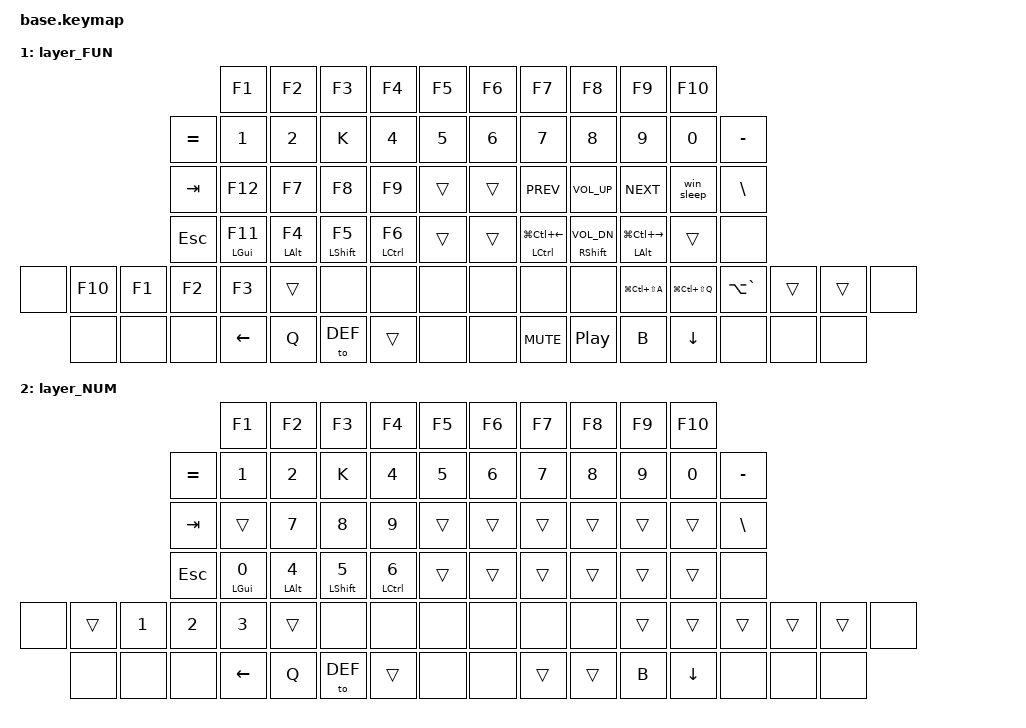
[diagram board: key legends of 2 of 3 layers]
#include <behaviors.dtsi>
#include <dt-bindings/zmk/keys.h>
#include "zmk-helpers/key-labels/glove80.h"

#include <dt-bindings/zmk/bt.h>

#include "zmk-helpers/helper.h"
#include "zmk-helpers/unicode-chars/ainain

setting code-chars/german.dtsi"

#define Layer_DEF 0
#define Layer_NAV 1
#define Layer_FN 2
#define Layer_SYS 4

#include "combos.dtsi"  // requires layer aliases
#include "mouse.dtsi"
#include "extra_keys.h"

/* Global settings */

#define QUICK_TAP_MS 175


/* Homerow modsrrrrrrrtttttttttmmmmmmmmmmm|IIIrI */

#define KEYS_L LT0 LT1 LT2 LT3 LT4 LM0 LM1 LM2 LM3 LM4 LB0 LB1 LB2 LB3 LB4 LF1 LF2 LF3 LF4 LF5 LN0 LN1 LN2 LN3 LN4 LN5 // left hand
#define KEYS_R RT0 RT1 RT2 RT3 RT4 RM0 RM1 RM2 RM3 RM4 RB0 RB1 RB2 RB3 RB4 RF1 RF2 RF3 RF4 RF5 // right hand
#define THUMBS LH2 LH1 LH0 RH0 RH1 RH2                                      // thumbs

#define MAKE_HRM(NAME, HOLD, TAP, TRIGGER_POS) \
    ZMK_HOLD_TAP(NAME, \
        flavor = "balanced"; \
        tapping-term-ms = <280>; \
        quick-tap-ms = <QUICK_TAP_MS>; \
        require-prior-idle-ms = <350>; \
        bindings = <HOLD>, <TAP>; \
        hold-trigger-key-positions = <TRIGGER_POS>; \ 
        hold-trigger-on-release; \
    )
MAKE_HRM(hml, &kp, &kp, KEYS_R THUMBS)  // left-hand HRMs
MAKE_HRM(hmr, &kp, &kp, KEYS_L THUMBS)  // right-hand HRMs

MAKE_HRM(hml_repeat, &kp, &key_repeat, KEYS_R THUMBS)  // used for HRM-combo
MAKE_HRM(hmr_lpar_lt, &kp, &lpar_lt, KEYS_L THUMBS)    // "    "   "   "
MAKE_HRM(hmr_rpar_gt, &kp, &rpar_gt, KEYS_L THUMBS)    // "    "   "   "

/* Nav cluster */

// long-tap action on hold, short-tap action on all interrupts
#define MT_CORE \
    flavor = "tap-preferred"; \
    tapping-term-ms = <220>; \
    quick-tap-ms = <220>; \
    hold-trigger-key-positions = <0>;

&mt { MT_CORE };
ZMK_HOLD_TAP(mt_home, bindings = <&masked_home>, <&kp>; MT_CORE)
ZMK_HOLD_TAP(mt_end, bindings = <&masked_end>, <&kp>; MT_CORE)

#define NAV_LEFT  &mt_home 0   LEFT    // tap: left  | long-tap: beginning of line
#define NAV_RIGHT &mt_end 0    RIGHT   // tap: right | long-tap: end       of line
#define NAV_UP    &mt LC(HOME) UP      // tap: up    | long-tap: beginning of document
#define NAV_DOWN  &mt LC(END)  DOWN    // tap: down  | long-tap: end       of document
#define NAV_BSPC  &mt LC(BSPC) BSPC    // tap: bspc  | long-tap: delete word backward
#define NAV_DEL   &mt LC(DEL)  DEL     // tap: del   | long-tap: delete word forward

// mask CTRL when holding left/right to avoid accidental jumps to beginning/end of document
#define MASK_MODS(NAME, MODS, BINDING) \
    ZMK_MOD_MORPH(NAME, \
        bindings = <BINDING>, <BINDING>; \
        mods = <MODS>; \
    )
MASK_MODS(masked_home, (MOD_LCTL), &kp HOME)
MASK_MODS(masked_end,  (MOD_LCTL), &kp END)

/* Caps-word, num-word and smart-mouse */

// tap: sticky-shift | shift + tap/ double-tap: caps-word | hold: shift
ZMK_MOD_MORPH(smart_shft,
    bindings = <&sk LSHFT>, <&caps_word>;
    mods = <(MOD_LSFT)>;
)
&caps_word {  // mods deactivate caps-word, requires PR #1451
    /delete-property/ ignore-modifiers;
};

// tap: num-word | double-tap: sticky num-layer | hold: num-layer
#define SMART_NUM &smart_num NUM 0
ZMK_HOLD_TAP(smart_num,
    flavor = "balanced";
    tapping-term-ms = <200>;
    quick-tap-ms = <QUICK_TAP_MS>;
    bindings = <&mo>, <&num_dance>;
)
ZMK_TAP_DANCE(num_dance,
    tapping-term-ms = <200>;
    bindings = <&num_word>, <&sl NUM>;  // reverse this for sticky-num on single tap
)
&num_word {  // num-word, requires PR #1451
    layers = <NUM>;
    continue-list = <BSPC DEL DOT COMMA PLUS MINUS STAR FSLH EQUAL>;
};

// smart-mouse, requires PR #1366
ZMK_TRI_STATE(smart_mouse,
    bindings = <&tog MOUSE>, <&none>, <&tog MOUSE>;
    ignored-key-positions = <LT1 LT3 RT0 RT1 RT2 RT3 RT4 RM1 RM2 RM3 RB1 RB2 RB3 RH0 RH1>;
    ignored-layers = <MOUSE>;
)

/* Custom behaviors */

// Alt+Tab swapper, requires PR #1366
ZMK_TRI_STATE(swapper,
    bindings = <&kt LALT>, <&kp TAB>, <&kt LALT>;
    ignored-key-positions = <LT2>;
)

// Sticky layer + sticky shift (workaround for issue #1421)
ZMK_STICKY_KEY(sls,
    release-after-ms = <1000>;
    bindings = <&uc_shift>;
    ignore-modifiers;
)
ZMK_MACRO(uc_shift,
    wait-ms = <0>;
    tap-ms = <1>;
    bindings = <&macro_press &mo UC &kp LSHFT>
             , <&macro_pause_for_release>
             , <&macro_release &mo UC &kp LSHFT>;
)

// reuse basic mod-morph scheme
#define SIMPLE_MORPH(NAME, MOD, BINDING1, BINDING2) \
    ZMK_MOD_MORPH(NAME, \
        mods = <(MOD_L ## MOD|MOD_R ## MOD)>; \
        bindings = <BINDING1>, <BINDING2>; \
    )

// tap: comma | shift + tap: semicolon | ctrl + shift + tap: <
SIMPLE_MORPH(comma_morph, SFT, &kp COMMA, &comma_inner_morph)
SIMPLE_MORPH(comma_inner_morph, CTL, &kp SEMICOLON, &kp LESS_THAN)

// tap: dot | shift + tap: colon | ctrl + shift + tap: >
SIMPLE_MORPH(dot_morph, SFT, &kp DOT, &dot_inner_morph)
SIMPLE_MORPH(dot_inner_morph, CTL, &kp COLON, &kp GREATER_THAN)

// tap: qmark | shift + tap: excl
SIMPLE_MORPH(qexcl, SFT, &kp QMARK, &kp EXCL)
SIMPLE_MORPH(quote, SFT, &kp LS(SINGLE_QUOTE), &kp SINGLE_QUOTE)

// tap: left/right parenthesis | shft + tap: less-than/greater-than
SIMPLE_MORPH(lpar_lt, SFT, &kp LPAR, &kp LT)
SIMPLE_MORPH(rpar_gt, SFT, &kp RPAR, &kp GT)

// tap: space | shift + tap: dot -> space -> sticky shift | hold: activate layer
ZMK_HOLD_TAP(lt_spc,
    flavor = "balanced";
    tapping-term-ms = <200>;
    quick-tap-ms = <QUICK_TAP_MS>;
    bindings = <&mo>, <&spc_morph>;
)
SIMPLE_MORPH(spc_morph, SFT, &kp SPACE, &dot_spc)
ZMK_MACRO(dot_spc,
    wait-ms = <0>;
    tap-ms = <5>;
    bindings = <&kp DOT &kp SPACE &sk LSHFT>;
)

// tap: backspace | lshft + tap: delete | rshft + tap: shift-delete
ZMK_MOD_MORPH(bs_del,
    bindings = <&kp BSPC>, <&kp DEL>;
    mods = <(MOD_LSFT|MOD_RSFT)>;
    keep-mods = <MOD_RSFT>;
)

// tap: copy | double-tap: cut
ZMK_TAP_DANCE(copy_cut,
    tapping-term-ms = <200>;
    bindings = <&kp LC(INS)>, <&kp LC(X)>;
)

// Windows sleep key
ZMK_MACRO(win_sleep,
    wait-ms = <500>;
    tap-ms = <50>;
    bindings = <&kp LG(X) &kp U &kp S>;
)

// misc aliases
#define CANCEL      &kp K_CANCEL             // cancel caps-word, num-word and smart-mouse
#define DSK_PREV    &hmr LCTRL LG(LC(LEFT))   // previous desktop
#define DSK_NEXT    &hmr LALT LG(LC(RIGHT)) // next     desktop
#define PIN_WIN     &kp LG(LC(LS(Q)))        // pin window across desktops
#define PIN_APP     &kp LG(LC(LS(A)))        // pin application across desktops
#define DSK_MGR     &kp LA(GRAVE)            // desktop manager
#define VOL_DOWN    &hmr RSHFT C_VOL_DN


/* Keymap */                             

/ {
    keymap {
        compatible = "zmk,keymap";
                layer_DEF {
            bindings = <
//╭─────────────┬─────────────┬─────────────┬─────────────┬─────────────╮                                                                                                            ╭─────────────┬─────────────┬─────────────┬──────────────┬─────────────╮
     &kp F1         &kp F2        &kp F3       &kp F4        &kp F5                                                                                                                    &kp F6        &kp F7        &kp F8        &kp F9        &kp F10 
//├─────────────┼─────────────┼─────────────┼─────────────┼─────────────┼───────────╮                                                                                 ╭──────────────┼─────────────┼─────────────┼─────────────┼──────────────┼─────────────┤
     &kp EQUAL      &kp N1        &kp N2       &kp K         &kp N4        &kp N5                                                                                       &kp N6         &kp N7        &kp N8        &kp N9        &kp N0        &kp MINUS                
//╰─────────────┴─────────────┴─────────────┴─────────────┴─────────────┴───────────╯                                                                                 ╰──────────────┴─────────────┴─────────────┴─────────────┴──────────────┴─────────────╯
         
//╭─────────────┬──────────────┬─────────────┬─────────────┬─────────────┬────────────╮                                                                               ╭─────────────┬─────────────┬─────────────┬─────────────┬──────────────┬──────────────╮
    &none         &kp ESC        &kp G         &kp H         &kp C          &kp Z                                                                                          &trans       &kp V         &kp L         &kp B         &kp SQT       &none  
//├─────────────┤──────────────┼─────────────┼─────────────┼─────────────┼────────────┤                                                                               ├─────────────┼─────────────┼─────────────┼─────────────┼──────────────┼──────────────┤
    &none         &hml LGUI O    &hml LALT A   &hml LSHFT I  &hml LCTRL N   &qexcl                                                                                         &trans       &hmr LCTRL T  &hmr RSHFT R  &hmr LALT E   &hmr LGUI S   &none  
//├─────────────┤──────────────┼─────────────┼─────────────┼─────────────┼────────────┤ ╭──────────────┬─────────────┬───────╮╭────────┬──────────────┬─────────────╮ ├─────────────┼─────────────┼─────────────┼─────────────┼──────────────┼──────────────┤
    &kp LSHFT     &kp J          &kp F         &kp U         &kp P          &trans         &mo NAV       &lt FN RET    &none    &none     &mo SYS       &mo NUM           &trans        &kp M         &kp D         &kp Y         &kp X         &kp RSHFT  
//├─────────────┼──────────────┤─────────────┼─────────────┤─────────────┼────────────╯ ├──────────────┼─────────────┼───────┤├────────┼──────────────┼─────────────┤ ╰─────────────┼─────────────┼─────────────┤─────────────┼──────────────┤──────────────┤
    &bootloader   &none         &comma_morph   &quote        &kp Q                         &kp SPACE     &kp BACKSPACE &none    &none     &none         &kp TAB                         &kp W         &kp RET      &dot_morph     &none         &bootloader
//╰─────────────┴──────────────┴─────────────┴─────────────┴─────────────╯              ╰──────────────┴─────────────┴───────╯╰────────┴──────────────┴─────────────╯               ╰─────────────┴─────────────┴─────────────┴──────────────┴──────────────╯                                           
            >;
        };
    };
};
    
/ {
    keymap {
        compatible = "zmk,keymap";
                layer_NAV {      
                    bindings = <             
//╭──────╮ ╭─────────────┬─────────────┬─────────────┬─────────────┬─────────────╮ ╭──────╮ ╭─────────────┬─────────────┬─────────────┬─────────────┬─────────────╮ ╭──────╮
    \
                &kp F1    &kp F2 &kp F3 &kp F4 &kp F5                 &kp F6 &kp F7 &kp F8 &kp F9 &kp F10 \
                &kp EQUAL &kp N1 &kp N2 &kp K &kp N4 &kp N5   &kp N6 &kp N7 &kp N8 &kp N9 &kp N0 &kp MINUS \
                &kp TAB     &trans           &trans           &kp LS(TAB)   &swapper      &trans             X_MT     &kp PG_UP     NAV_BSPC      NAV_UP        NAV_DEL       &trans             &kp BACKSLASH
//├──────┤ ├─────────────┼─────────────┼─────────────┼─────────────┼─────────────┤ ├──────┤ ├─────────────┼─────────────┼─────────────┼─────────────┼─────────────┤ ├──────┤
    &kp ESC     &sk LGUI      &sk LALT      &sk LSHFT     &sk LCTRL     &trans             X_MM     &kp PG_DN     NAV_LEFT      NAV_DOWN      NAV_RIGHT     &kp RET         &none
//├──────┤ ├─────────────┼─────────────┼─────────────┼─────────────┼─────────────┤ ├──────┤ ├─────────────┼─────────────┼─────────────┼─────────────┼─────────────┤ ├──────┤
    &none     &trans           &trans           &trans           &trans           &trans             &none &none &none       &none &none &none     &kp INS       &kp TAB       &kp LT        &kp GT        &trans             &none
//├──────┤ ╰─────────────┼─────────────┴─────────────┼─────────────┼─────────────┤ ├──────┤ ├─────────────┼─────────────┼─────────────┴───────────────────────────╯ ├──────┤
    &none &none &none &kp LEFT &kp Q                                               &to DEF           &trans              &none &none     &trans           CANCEL                                                    &kp B &kp DOWN &none &none &none
//╰──────╯                                           ╰─────────────┴─────────────╯ ╰──────╯ ╰─────────────┴─────────────╯                                           ╰──────╯
>;
        };
    };
};

/ {
    keymap {
        compatible = "zmk,keymap";
                layer_FUN {   
                    bindings = <
//╭──────╮ ╭─────────────┬─────────────┬─────────────┬─────────────┬─────────────╮ ╭──────╮ ╭─────────────┬─────────────┬─────────────┬─────────────┬─────────────╮ ╭──────╮
    \
                &kp F1    &kp F2 &kp F3 &kp F4 &kp F5                 &kp F6 &kp F7 &kp F8 &kp F9 &kp F10 \
                &kp EQUAL &kp N1 &kp N2 &kp K &kp N4 &kp N5   &kp N6 &kp N7 &kp N8 &kp N9 &kp N0 &kp MINUS \
                &kp TAB     &kp F12       &kp F7        &kp F8        &kp F9        &trans                  &trans           &kp C_PREV    &kp C_VOL_UP  &kp C_NEXT    &win_sleep      &kp BACKSLASH
//├──────┤ ├─────────────┼─────────────┼─────────────┼─────────────┼─────────────┤ ├──────┤ ├─────────────┼─────────────┼─────────────┼─────────────┼─────────────┤ ├──────┤
    &kp ESC     &hml LGUI F11 &hml LALT F4  &hml LSHFT F5 &hml LCTRL F6 &trans                  &trans           DSK_PREV      VOL_DOWN      DSK_NEXT      &trans             &none
//├──────┤ ├─────────────┼─────────────┼─────────────┼─────────────┼─────────────┤ ├──────┤ ├─────────────┼─────────────┼─────────────┼─────────────┼─────────────┤ ├──────┤
    &none     &kp F10       &kp F1        &kp F2        &kp F3        &trans             &none &none &none       &none &none &none     PIN_APP       PIN_WIN       DSK_MGR       &trans           &trans             &none
//├──────┤ ╰─────────────┼─────────────┴─────────────┼─────────────┼─────────────┤ ├──────┤ ├─────────────┼─────────────┼─────────────┴───────────────────────────╯ ├──────┤
    &none &none &none &kp LEFT &kp Q                                               &to DEF           &trans              &none &none     &kp C_MUTE    &kp C_PP                                                  &kp B &kp DOWN &none &none &none
//╰──────╯                                           ╰─────────────┴─────────────╯ ╰──────╯ ╰─────────────┴─────────────╯                                           ╰──────╯
>;
        };
    };
};

/ {
    keymap {
        compatible = "zmk,keymap";
                layer_NUM {  
                    bindings = <
//╭──────╮ ╭─────────────┬─────────────┬─────────────┬─────────────┬─────────────╮ ╭──────╮ ╭─────────────┬─────────────┬─────────────┬─────────────┬─────────────╮ ╭──────╮
    \
                &kp F1    &kp F2 &kp F3 &kp F4 &kp F5                 &kp F6 &kp F7 &kp F8 &kp F9 &kp F10 \
                &kp EQUAL &kp N1 &kp N2 &kp K &kp N4 &kp N5   &kp N6 &kp N7 &kp N8 &kp N9 &kp N0 &kp MINUS \
                &kp TAB     &trans           &kp N7        &kp N8        &kp N9        &trans                  &trans           &trans           &trans           &trans           &trans             &kp BACKSLASH
//├──────┤ ├─────────────┼─────────────┼─────────────┼─────────────┼─────────────┤ ├──────┤ ├─────────────┼─────────────┼─────────────┼─────────────┼─────────────┤ ├──────┤
    &kp ESC     &hml LGUI N0  &hml LALT N4  &hml LSHFT N5 &hml LCTRL N6 &trans                  &trans           &trans           &trans           &trans           &trans             &none
//├──────┤ ├─────────────┼─────────────┼─────────────┼─────────────┼─────────────┤ ├──────┤ ├─────────────┼─────────────┼─────────────┼─────────────┼─────────────┤ ├──────┤
    &none     &trans           &kp N1        &kp N2        &kp N3        &trans             &none &none &none       &none &none &none     &trans           &trans           &trans           &trans           &trans             &none
//├──────┤ ╰─────────────┼─────────────┴─────────────┼─────────────┼─────────────┤ ├──────┤ ├─────────────┼─────────────┼─────────────┴───────────────────────────╯ ├──────┤
    &none &none &none &kp LEFT &kp Q                                               &to DEF           &trans              &none &none     &trans           &trans                                                       &kp B &kp DOWN &none &none &none
//╰──────╯                                           ╰─────────────┴─────────────╯ ╰──────╯ ╰─────────────┴─────────────╯                                           ╰──────╯
>;
        };
    };
};

// / {
//     keymap {
//         compatible = "zmk,keymap";
//                 layer_SYS {  
//                     bindings = <
// //╭──────╮ ╭─────────────┬─────────────┬─────────────┬─────────────┬─────────────╮ ╭──────╮ ╭─────────────┬─────────────┬─────────────┬─────────────┬─────────────╮ ╭──────╮
//     \
//                 &kp F1    &kp F2 &kp F3 &kp F4 &kp F5                 &kp F6 &kp F7 &kp F8 &kp F9 &kp F10 \
//                 &kp EQUAL &kp N1 &kp N2 &kp K &kp N4 &kp N5   &kp N6 &kp N7 &kp N8 &kp N9 &kp N0 &kp MINUS \
//                 &kp TAB                                &bt BT_SEL 0 &bt BT_SEL 1 &bt BT_SEL 2 &bt BT_SEL 3 &bt BT_CLR                                X_MT     &trans           &trans           &trans           &trans           &trans             &kp BACKSLASH
// //├──────┤ ├─────────────┼─────────────┼─────────────┼─────────────┼─────────────┤ ├──────┤ ├─────────────┼─────────────┼─────────────┼─────────────┼─────────────┤ ├──────┤
//     &kp ESC     &trans           &trans           &trans           &trans           &bootloader     X_MM     &bootloader   &trans           &trans           &trans           &trans             &none
// //├──────┤ ├─────────────┼─────────────┼─────────────┼─────────────┼─────────────┤ ├──────┤ ├─────────────┼─────────────┼─────────────┼─────────────┼─────────────┤ ├──────┤
//     &none     &trans           &trans           &trans           &trans           &sys_reset      &none &none &none       &none &none &none     &sys_reset    &trans           &trans           &trans           &trans             &none
// //├──────┤ ╰─────────────┼─────────────┴─────────────┼─────────────┼─────────────┤ ├──────┤ ├─────────────┼─────────────┼─────────────┴───────────────────────────╯ ├──────┤
//     &none &none &none &kp LEFT &kp Q                                               &to DEF           &trans              &none &none     &trans           &trans                                                       &kp B &kp DOWN &none &none &none
// //╰──────╯                                           ╰─────────────┴─────────────╯ ╰──────╯ ╰─────────────┴─────────────╯                                           ╰──────╯
// >;
//         };
//     };
// };


// ZMK_LAYER(mouse,
// //╭──────╮ ╭─────────────┬─────────────┬─────────────┬─────────────┬─────────────╮ ╭──────╮ ╭─────────────┬─────────────┬─────────────┬─────────────┬─────────────╮ ╭──────╮
//     \
                // &kp F1    &kp F2 &kp F3 &kp F4 &kp F5                 &kp F6 &kp F7 &kp F8 &kp F9 &kp F10 \
                // &kp EQUAL &kp N1 &kp N2 &kp K &kp N4 &kp N5   &kp N6 &kp N7 &kp N8 &kp N9 &kp N0 &kp MINUS \
                // &kp TAB     &trans           &trans           &trans           &trans           &trans             X_MT     U_WH_L        U_WH_D        U_MS_U         U_WH_U       U_WH_R          &kp BACKSLASH
// //├──────┤ ├─────────────┼─────────────┼─────────────┼─────────────┼─────────────┤ ├──────┤ ├─────────────┼─────────────┼─────────────┼─────────────┼─────────────┤ ├──────┤
//     &kp ESC     &trans           &trans           &trans           &trans           &trans             X_MM     &trans           U_MS_L        U_MS_D         U_MS_R       &trans             &none
// //├──────┤ ├─────────────┼─────────────┼─────────────┼─────────────┼─────────────┤ ├──────┤ ├─────────────┼─────────────┼─────────────┼─────────────┼─────────────┤ ├──────┤
//     &none     &trans           &trans           &trans           &trans           &trans             &none &none &none       &none &none &none     &trans           &mkp MB4      &mkp MCLK      &mkp MB5     &trans             &none
// //├──────┤ ╰─────────────┼─────────────┴─────────────┼─────────────┼─────────────┤ ├──────┤ ├─────────────┼─────────────┼─────────────┴───────────────────────────╯ ├──────┤
//     &none &none &none &kp LEFT &kp Q                                               &to DEF           &trans              &none &none     &mkp LCLK     &mkp RCLK                                                 &kp B &kp DOWN &none &none &none
// //╰──────╯                                           ╰─────────────┴─────────────╯ ╰──────╯ ╰─────────────┴─────────────╯                                           ╰──────╯
// )

/* vim: set ft=c tw=174: */
